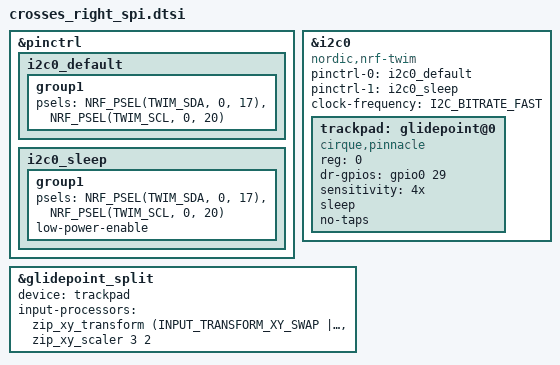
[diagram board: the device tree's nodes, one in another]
/*
 * Copyright (c) 2021 The ZMK Contributors
 *
 * SPDX-License-Identifier: MIT
 */

#include <input/processors.dtsi>
#include <dt-bindings/zmk/input_transform.h>
#include "crosses.dtsi"

// Configure custom spi for the Right side



&pinctrl {
    /* configuration for i2c0 device, default state */
    i2c0_default: i2c0_default {
        group1 {
            psels = <NRF_PSEL(TWIM_SDA, 0, 17)>,
                <NRF_PSEL(TWIM_SCL, 0, 20)>;
        };
    };

    i2c0_sleep: i2c0_sleep {
        group1 {
            psels = <NRF_PSEL(TWIM_SDA, 0, 17)>,
                <NRF_PSEL(TWIM_SCL, 0, 20)>;
            low-power-enable;
        };
    };
};

&i2c0 {
    compatible = "nordic,nrf-twim"; // I2C controller instead of generic
    status = "okay";
    pinctrl-0 = <&i2c0_default>;
    pinctrl-1 = <&i2c0_sleep>;
    pinctrl-names = "default", "sleep";
    clock-frequency = <I2C_BITRATE_FAST>;

    trackpad: glidepoint@0 {
        compatible = "cirque,pinnacle";
        reg = <0>;
        status = "okay";
        dr-gpios = <&gpio0 29 (GPIO_ACTIVE_HIGH)>;
        sensitivity = "4x";
        sleep;
        no-taps;
    };
};

&glidepoint_split {
	device = <&trackpad>;
	input-processors = <&zip_xy_transform (INPUT_TRANSFORM_XY_SWAP | INPUT_TRANSFORM_X_INVERT | INPUT_TRANSFORM_Y_INVERT)>, <&zip_xy_scaler 3 2>;
};
